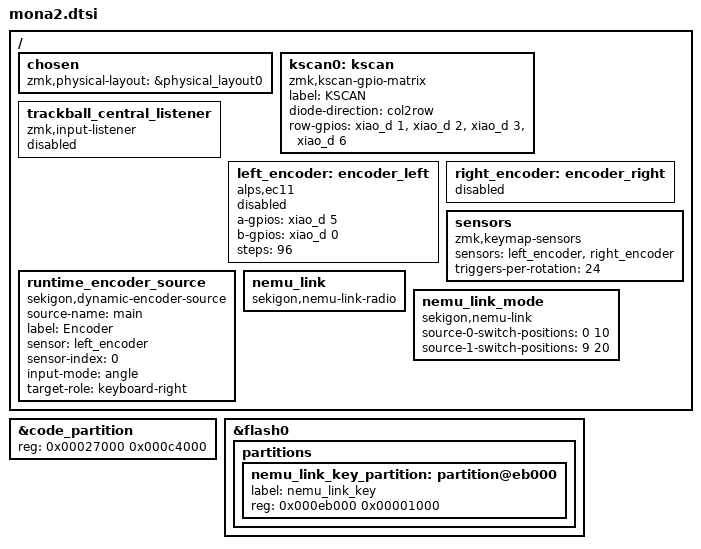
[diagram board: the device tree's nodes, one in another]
#include <dt-bindings/zmk/matrix_transform.h>
#include <dt-bindings/zmk/pointing.h>
#include <input/processors.dtsi>
#include <dt-bindings/zmk/input_transform.h>
#include <physical_layouts.dtsi>
/* NOTE: <input/processors/runtime-input-processor.dtsi> は最終的に
   modifiers.h を引き込み RC(keycode) を 1 引数で再定義するため、
   このファイル内のマトリクス RC(row,col) と衝突する。
   そのため runtime-input-processor.dtsi は overlay 側で
   `#include "mona2.dtsi"` の後に include すること。 */
#include "mona2_layouts.dtsi"

/ {
    chosen {
        zmk,physical-layout = &physical_layout0;
    };

    kscan0: kscan {
        compatible = "zmk,kscan-gpio-matrix";
        label = "KSCAN";
        diode-direction = "col2row";
            row-gpios
                = <&xiao_d 1 (GPIO_ACTIVE_HIGH | GPIO_PULL_DOWN)> 
                , <&xiao_d 2 (GPIO_ACTIVE_HIGH | GPIO_PULL_DOWN)> 
                , <&xiao_d 3 (GPIO_ACTIVE_HIGH | GPIO_PULL_DOWN)> 
                , <&xiao_d 6 (GPIO_ACTIVE_HIGH | GPIO_PULL_DOWN)> 			
                ;
    };

    //right hand trackball
    trackball_central_listener: trackball_central_listener {
        compatible = "zmk,input-listener";
        status = "disabled";
        /* DYA Studio で動的に編集できるよう、入力プロセッサは
           overlay 側で &mouse_runtime_input_processor /
           &scroll_runtime_input_processor へ委譲する */
    };

    left_encoder: encoder_left {
        compatible = "alps,ec11";
        a-gpios = <&xiao_d 5 (GPIO_ACTIVE_HIGH | GPIO_PULL_UP)>;
        b-gpios = <&xiao_d 0 (GPIO_ACTIVE_HIGH | GPIO_PULL_UP)>;
        steps = <96>;
        status = "disabled";
    };

    right_encoder: encoder_right {
        status = "disabled";
    };

    sensors: sensors {
        compatible = "zmk,keymap-sensors";
        sensors = <&left_encoder &right_encoder>;
        triggers-per-rotation = <24>;
    };

    /* sekigon dynamic-encoder source。未設定時は keymap の静的 sensor-bindings
       (&scroll_encoder / &inc_dec_kp) にフォールスルーし、Studio で設定した
       レイヤーのみ動的上書きされる。sensor-index は上記 sensors リスト内の index (0=left)。 */
    runtime_encoder_source: runtime_encoder_source {
        compatible = "sekigon,dynamic-encoder-source";
        source-name = "main";
        label = "Encoder";
        sensor = <&left_encoder>;
        sensor-index = <0>;
        input-mode = "angle";
        target-role = "keyboard-right";
    };

    /* nemu-link: 両 half 共通の ESB radio ノード (全 peer で一致させる) */
    nemu_link: nemu_link {
        compatible = "sekigon,nemu-link-radio";
    };

    /* nemu-link: ドングル不在時に各 half 単体で BLE/ESB を切り替える chord。
       同じ source 上で同時長押しする global key position。
       source-0 = 左手 (最左列 2 キー: pos0,10)、source-1 = 右手 (最右列 2 キー: pos9,20) */
    nemu_link_mode: nemu_link_mode {
        compatible = "sekigon,nemu-link";
        source-0-switch-positions = <0 10>;
        source-1-switch-positions = <9 20>;
    };

};

/* nemu-link: 各 peripheral の application flash 末尾 4KiB を鍵保存領域にする。
   xiao_ble (nRF52840, UF2 SD v7 layout) は code partition が
   0x27000..0xebfff なので末尾 4KiB を nemu_link_key として分離する。 */
&code_partition {
    reg = <0x00027000 0x000c4000>;
};

&flash0 {
    partitions {
        nemu_link_key_partition: partition@eb000 {
            label = "nemu_link_key";
            reg = <0x000eb000 0x00001000>;
        };
    };
};
